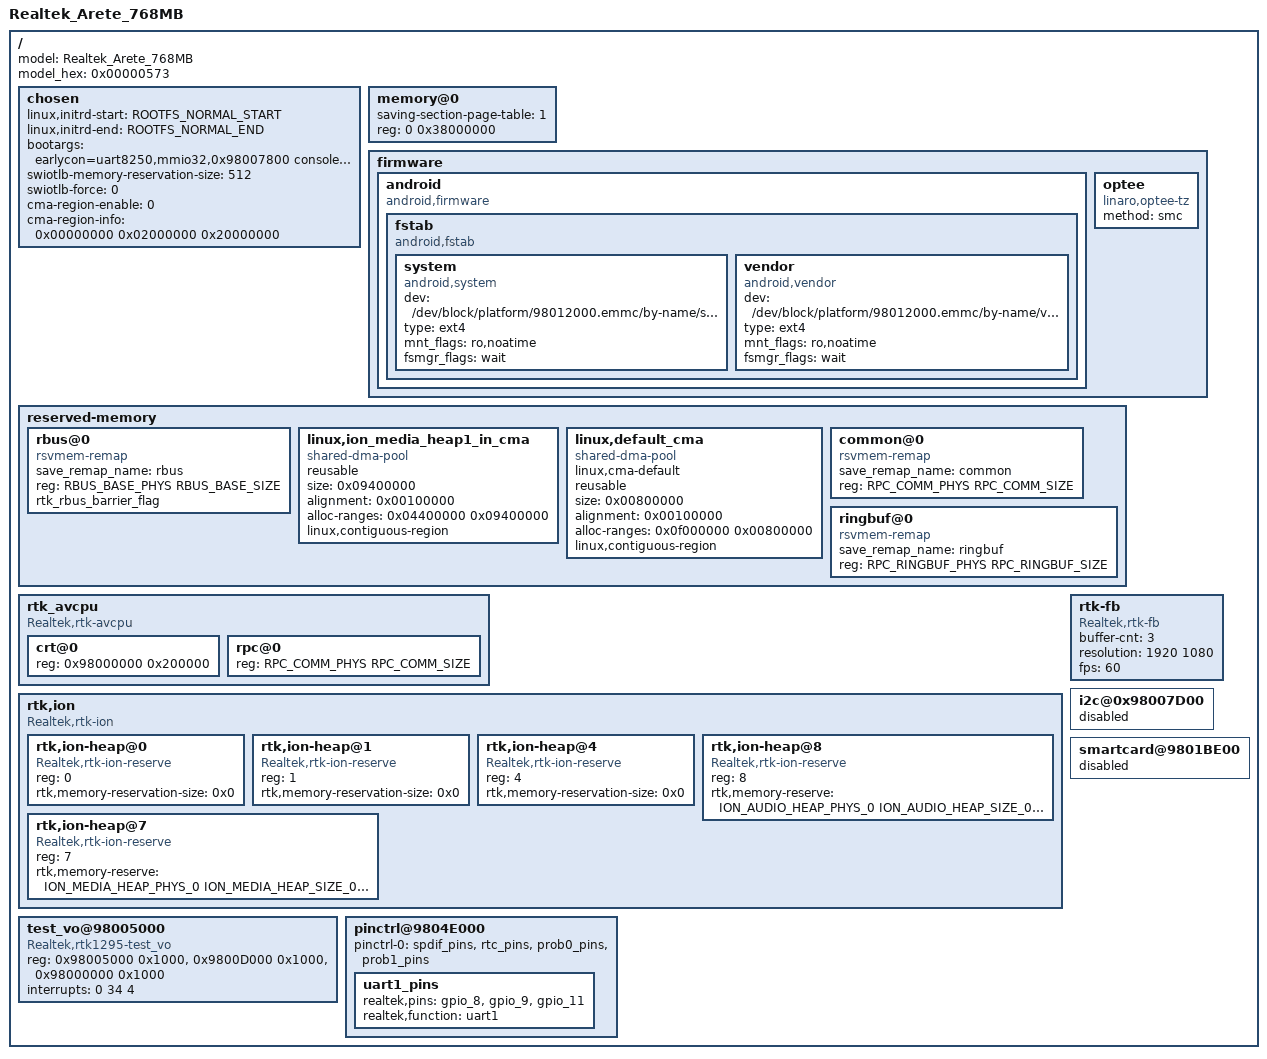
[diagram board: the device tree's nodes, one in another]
/dts-v1/;
#include <dt-bindings/soc/rtd139x,memory.h>

/memreserve/ SYS_BOOTCODE_MEMBASE SYS_BOOTCODE_MEMSIZE;
/memreserve/ RPC_COMM_PHYS RPC_COMM_SIZE;
/memreserve/ RPC_RINGBUF_PHYS RPC_RINGBUF_SIZE;
/memreserve/ ROOTFS_NORMAL_START ROOTFS_NORMAL_SIZE;
/memreserve/ ACPU_IDMEM_PHYS ACPU_IDMEM_SIZE;

#define MEDIA_REQ_SIZE_0 (0x01000000) // 16M
#define ION_MEDIA_HEAP_PHYS_0 (MEM_SLOT(0, PHYS, MEDIA_REQ_SIZE_0))
#define ION_MEDIA_HEAP_SIZE_0 (MEM_SLOT(0, SIZE, MEDIA_REQ_SIZE_0))
#define ION_MEDIA_HEAP_FLAG_0 (MEM_SLOT(0, FLAG, MEDIA_REQ_SIZE_0))

#define AUDIO_REQ_SIZE_0 (0x00c00000) // 12M
#define ION_AUDIO_HEAP_PHYS_0 (MEM_SLOT(1, PHYS, AUDIO_REQ_SIZE_0))
#define ION_AUDIO_HEAP_SIZE_0 (MEM_SLOT(1, SIZE, AUDIO_REQ_SIZE_0))
#define ION_AUDIO_HEAP_FLAG_0 (MEM_SLOT(1, FLAG, AUDIO_REQ_SIZE_0))

#define MEDIA_REQ_SIZE_1 (0x00000000) // 0M
#define ION_MEDIA_HEAP_PHYS_1 (MEM_SLOT(2, PHYS, MEDIA_REQ_SIZE_1))
#define ION_MEDIA_HEAP_SIZE_1 (MEM_SLOT(2, SIZE, MEDIA_REQ_SIZE_1))
#define ION_MEDIA_HEAP_FLAG_1 (MEM_SLOT(2, FLAG, MEDIA_REQ_SIZE_1))

/memreserve/ ION_MEDIA_HEAP_PHYS_0  ION_MEDIA_HEAP_SIZE_0;
/memreserve/ ION_AUDIO_HEAP_PHYS_0  ION_AUDIO_HEAP_SIZE_0;

#include "rtd-139x.dtsi"

/ {
	model= "Realtek_Arete_768MB";
	model_hex= <0x00000573>;

	/*
	 * NOTE:
	 * <flag size base>
	 * flag: reserved
	 * size: unit is byte
	 * base: unit is byte
	 *
	 * Array size not over 8;
	 * You may change the max array size in KConfig,
	 * max CMA array size is CONFIG_CMA_AREAS+1.
	 *
	 * If cma-region-enable is enabled<1>,
	 * kernel driver will use cma-region-info to initial CMA memory.
	 *
	 * If cma-region-enable is disabled<0>,
	 * kernel driver will use cma= to initial CMA memory.
	 *
	 * if both setting is loaded, cma-region-info had higher priority.
	 */

	chosen {
		linux,initrd-start = <ROOTFS_NORMAL_START>;
		linux,initrd-end = <ROOTFS_NORMAL_END>;
		bootargs = "earlycon=uart8250,mmio32,0x98007800 console=ttyS0,115200 init=/init androidboot.hardware=hercules androidboot.storage=emmc loglevel=4 androidboot.selinux=permissive";
		swiotlb-memory-reservation-size = <512>; /*  512: 1MB,  2048: 4MB*/
		swiotlb-force = <0>; /* 0: SWIOTLB_NORMAL, 1: SWIOTLB_FORCE, 2: SWIOTLB_NO_FORCE */
		cma-region-enable = <0>;
		cma-region-info = <0x00000000 0x02000000 0x20000000>;
		/*cma-region-info = <0x00000000 0x01000000 0x12c00000>, <0x00000000 0x12c00000 0x20000000>;*/
	};

	memory@0 {
		device_type = "memory";
		saving-section-page-table = <1>;
		reg = <0 0x38000000>; /* 768 MB */
	};

	firmware {
		android {
			compatible = "android,firmware";
			fstab {
				compatible = "android,fstab";
				system {
					compatible = "android,system";
					dev = "/dev/block/platform/98012000.emmc/by-name/system";
					type = "ext4";
					mnt_flags = "ro,noatime";
					fsmgr_flags = "wait";
				};
				vendor {
					compatible = "android,vendor";
					dev = "/dev/block/platform/98012000.emmc/by-name/vendor";
					type = "ext4";
					mnt_flags = "ro,noatime";
					fsmgr_flags = "wait";
				};
			};
		};
		optee {
			compatible = "linaro,optee-tz";
			method = "smc";
		};
	};

	reserved-memory {
		#address-cells = <1>;
		#size-cells = <1>;
		ranges;

		rbus@0 {
			compatible = "rsvmem-remap";
			save_remap_name = "rbus";
			reg = <RBUS_BASE_PHYS RBUS_BASE_SIZE>;
			rtk_rbus_barrier_flag;
		};

		linux,ion_media_heap1_in_cma {
			compatible = "shared-dma-pool";
			reusable;
			size = <0x09400000>; /* size 148MB */
			alignment = <0x00100000>;
			alloc-ranges = <0x04400000 0x09400000>; /* offset 68MB, size 148MB */
			linux,contiguous-region;
		};

		linux,default_cma {
			compatible = "shared-dma-pool";
			linux,cma-default;
			reusable;
			size = <0x00800000>; /* size 8MB */
			alignment = <0x00100000>;
			alloc-ranges = <0x0f000000 0x00800000>; /* offset 240MB, size 8MB */
			linux,contiguous-region;
		};

		common@0 {
			compatible = "rsvmem-remap";
			save_remap_name = "common";
			reg = <RPC_COMM_PHYS RPC_COMM_SIZE>;
		};

		ringbuf@0 {
			compatible = "rsvmem-remap";
			save_remap_name = "ringbuf";
			reg = <RPC_RINGBUF_PHYS RPC_RINGBUF_SIZE>;
		};
	};

	rtk_avcpu {
		compatible = "Realtek,rtk-avcpu";
		#address-cells = <1>;
		#size-cells = <1>;
		ranges;

		crt@0 {
			reg = <0x98000000 0x200000>;
		};

		rpc@0 {
			reg = <RPC_COMM_PHYS RPC_COMM_SIZE>;
		};
	};

	rtk,ion {
		compatible = "Realtek,rtk-ion";
		#address-cells = <1>;
		#size-cells = <0>;

		rtk,ion-heap@0 { /* SYSTEM_HEAP */
			compatible = "Realtek,rtk-ion-reserve";
			reg = <0>;
			rtk,memory-reservation-size = <0x0>;
		};

		rtk,ion-heap@1 { /* System contig */
			compatible = "Realtek,rtk-ion-reserve";
			reg = <1>;
			rtk,memory-reservation-size = <0x0>;
		};

		rtk,ion-heap@4 { /* DMA_HEAP */
			compatible = "Realtek,rtk-ion-reserve";
			reg = <4>;
			rtk,memory-reservation-size = <0x0>;
		};

		rtk,ion-heap@8 { /* Audio */
			compatible = "Realtek,rtk-ion-reserve";
			reg = <8>;
			rtk,memory-reserve = <
				ION_AUDIO_HEAP_PHYS_0
				ION_AUDIO_HEAP_SIZE_0
				ION_AUDIO_HEAP_FLAG_0>;
		};

		rtk,ion-heap@7 { /* TYPE_MEDIA */
			compatible = "Realtek,rtk-ion-reserve";
			reg = <7>;
			rtk,memory-reserve = <
				ION_MEDIA_HEAP_PHYS_0
				ION_MEDIA_HEAP_SIZE_0
				ION_MEDIA_HEAP_FLAG_0>;
		};
	};

	rtk-fb {
		compatible = "Realtek,rtk-fb";
		buffer-cnt = <3>;
		resolution = <1920 1080>;
		fps = <60>;
	};

	test_vo@98005000 {
		compatible = "Realtek,rtk1295-test_vo";
		reg = <0x98005000 0x1000>,
			<0x9800D000 0x1000>,
			<0x98000000 0x1000>;
		interrupts = <0 34 4>;
	};

	pinctrl@9804E000 {
		pinctrl-names = "default";
		pinctrl-0 = <&spdif_pins>,
                        <&rtc_pins>,
			<&prob0_pins>,
			<&prob1_pins>;
		/*gpio_11 UR1_RTS_N*/
		uart1_pins: uart1_pins {
                        realtek,pins = "gpio_8",
                                "gpio_9",
				"gpio_11";
                        realtek,function = "uart1";
                };

	};

	i2c@0x98007D00 {
		status = "disabled";
	};

	smartcard@9801BE00 {
		status = "disabled";
	};

};

#include "rtd-139x-cpu-dvfs-arete.dtsi"
